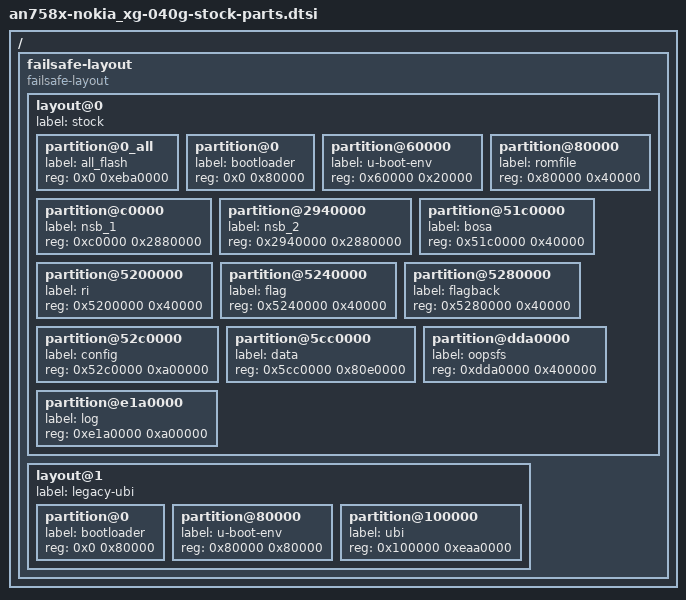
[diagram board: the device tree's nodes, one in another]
// SPDX-License-Identifier: GPL-2.0-only OR MIT

/ {
	failsafe-layout {
		compatible = "failsafe-layout";

		layout@0 {
			label = "stock";
			#address-cells = <1>;
			#size-cells = <1>;

			partition@0_all {
				label = "all_flash";
				reg = <0x0 0xeba0000>;
			};

			partition@0 {
				label = "bootloader";
				reg = <0x0 0x80000>;
			};

			partition@60000 {
				label = "u-boot-env";
				reg = <0x60000 0x20000>;
			};

			partition@80000 {
				label = "romfile";
				reg = <0x80000 0x40000>;
			};

			partition@c0000 {
				label = "nsb_1";
				reg = <0xc0000 0x2880000>;
			};

			partition@2940000 {
				label = "nsb_2";
				reg = <0x2940000 0x2880000>;
			};

			partition@51c0000 {
				label = "bosa";
				reg = <0x51c0000 0x40000>;
			};

			partition@5200000 {
				label = "ri";
				reg = <0x5200000 0x40000>;
			};

			partition@5240000 {
				label = "flag";
				reg = <0x5240000 0x40000>;
			};

			partition@5280000 {
				label = "flagback";
				reg = <0x5280000 0x40000>;
			};

			partition@52c0000 {
				label = "config";
				reg = <0x52c0000 0xa00000>;
			};

			partition@5cc0000 {
				label = "data";
				reg = <0x5cc0000 0x80e0000>;
			};

			partition@dda0000 {
				label = "oopsfs";
				reg = <0xdda0000 0x400000>;
			};

			partition@e1a0000 {
				label = "log";
				reg = <0xe1a0000 0xa00000>;
			};
		};

		layout@1 {
			label = "legacy-ubi";
			#address-cells = <1>;
			#size-cells = <1>;

			partition@0 {
				label = "bootloader";
				reg = <0x0 0x80000>;
			};

			partition@80000 {
				label = "u-boot-env";
				reg = <0x80000 0x80000>;
			};

			partition@100000 {
				label = "ubi";
				reg = <0x100000 0xeaa0000>;
			};
		};
	};
};
